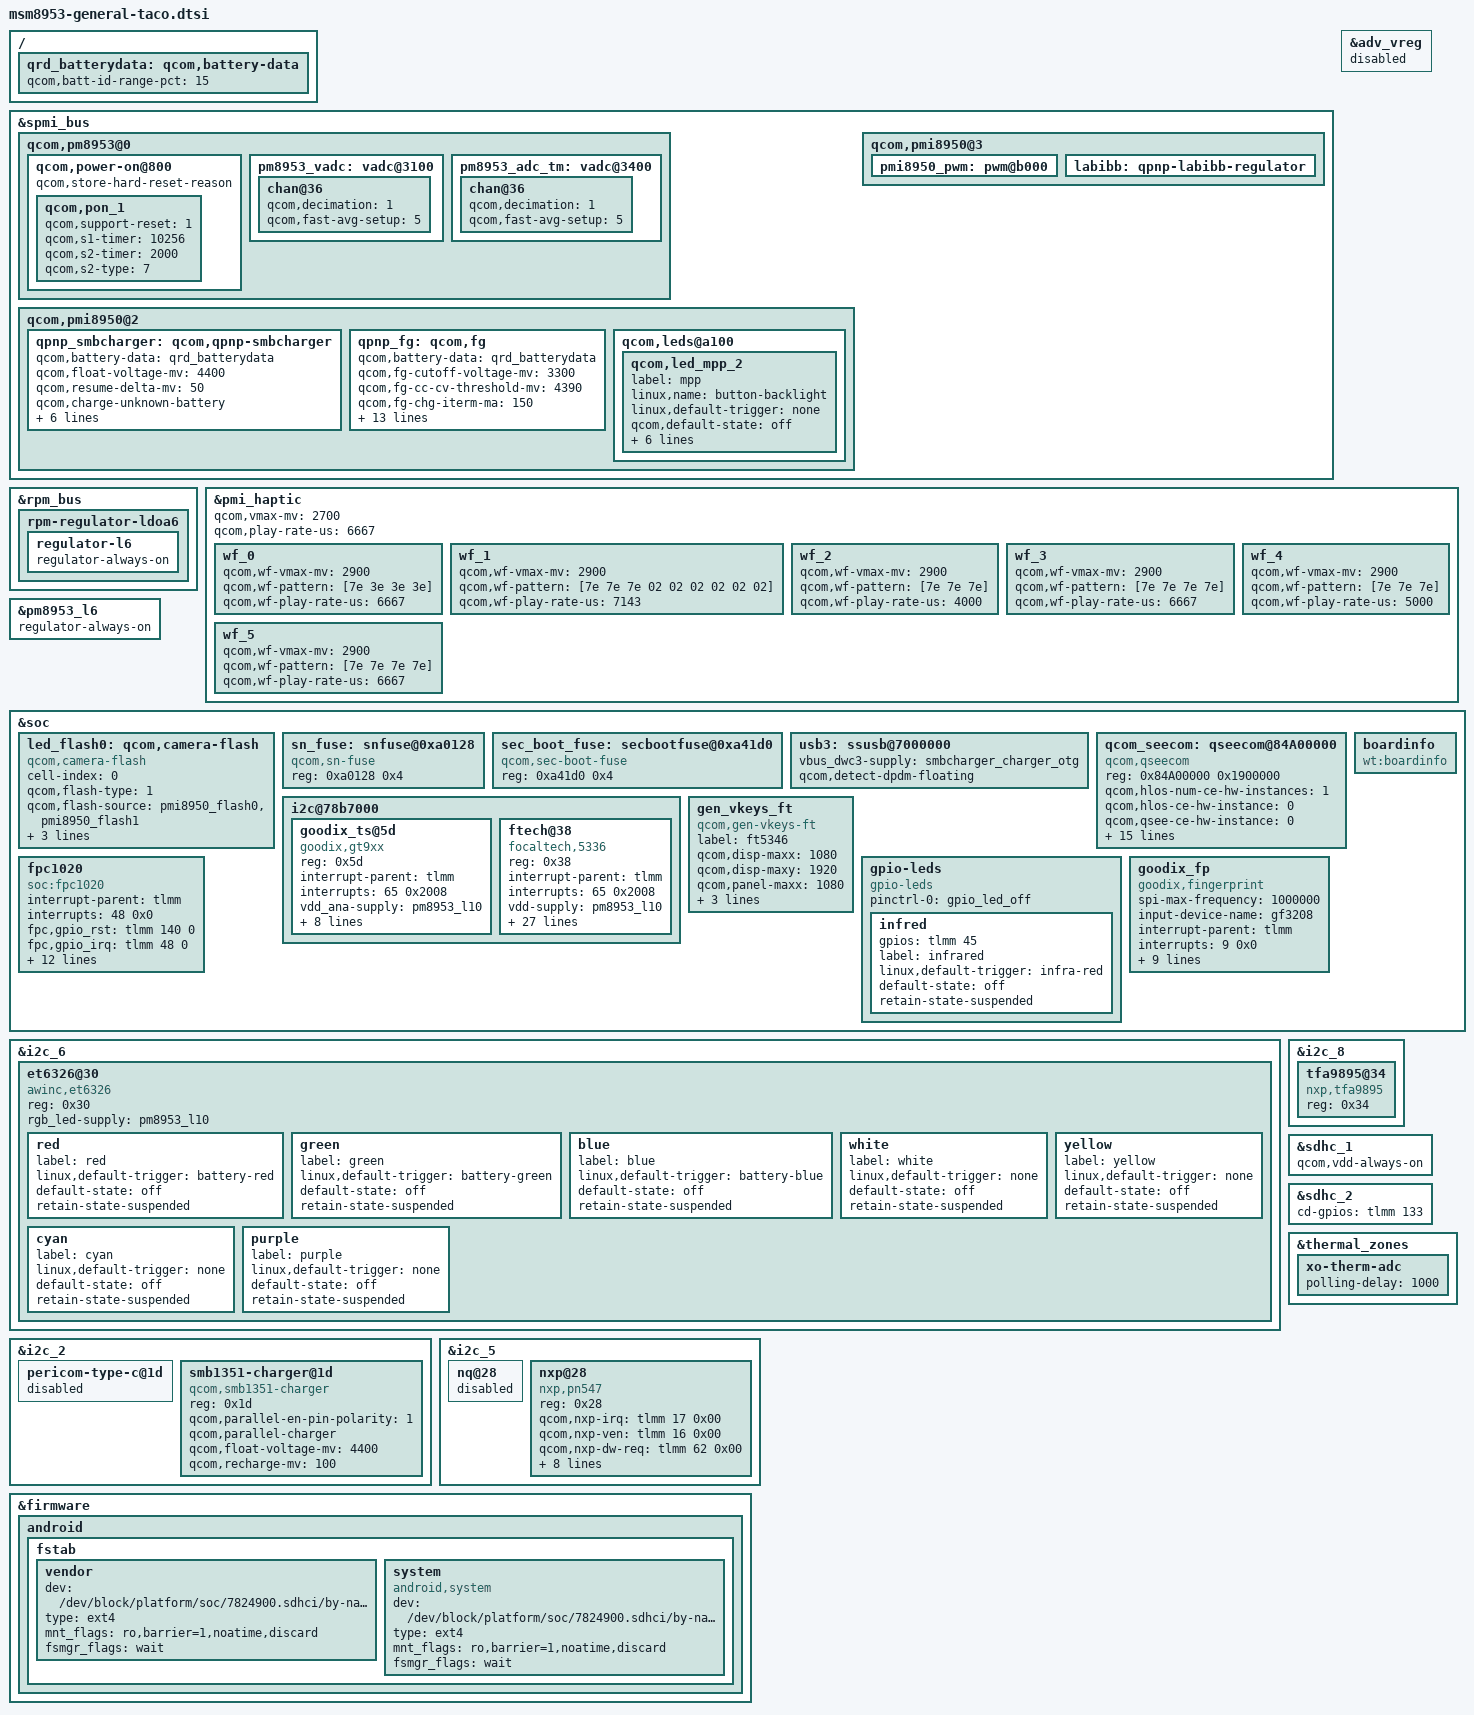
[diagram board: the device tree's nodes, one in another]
/* Copyright (c) 2017, The Linux Foundation. All rights reserved.
 *
 * This program is free software; you can redistribute it and/or modify
 * it under the terms of the GNU General Public License version 2 and
 * only version 2 as published by the Free Software Foundation.
 *
 * This program is distributed in the hope that it will be useful,
 * but WITHOUT ANY WARRANTY; without even the implied warranty of
 * MERCHANTABILITY or FITNESS FOR A PARTICULAR PURPOSE.  See the
 * GNU General Public License for more details.
 */

&spmi_bus {
	qcom,pm8953@0 {
		qcom,power-on@800 {
			qcom,store-hard-reset-reason;
			qcom,pon_1 {
				qcom,support-reset = <1>;
				qcom,s1-timer = <10256>;
				qcom,s2-timer = <2000>;
				qcom,s2-type = <7>;
		    };
	    };

 		/delete-node/ qcom,pm8953_typec@bf00;

		pm8953_vadc: vadc@3100 {
			chan@36 {
				qcom,decimation = <1>;
				qcom,fast-avg-setup = <5>;
			};
		};

		pm8953_adc_tm: vadc@3400 {
			chan@36 {
				qcom,decimation = <1>;
				qcom,fast-avg-setup = <5>;
			};
		};
    };

    qcom,pmi8950@2 {
        qpnp_smbcharger: qcom,qpnp-smbcharger {
            qcom,battery-data = <&qrd_batterydata>;
            qcom,float-voltage-mv = <4400>;
            qcom,resume-delta-mv = <50>;
            qcom,charge-unknown-battery;
            qcom,thermal-mitigation = <2000 1600 1500 1200 1000>;
            qcom,parallel-usb-min-current-ma = <1400>;
            qcom,parallel-usb-9v-min-current-ma = <900>;
            qcom,parallel-allowed-lowering-ma = <500>;
            qcom,autoadjust-vfloat;
            /delete-property/ qcom,chg-led-sw-controls;
            /delete-property/ qcom,chg-led-support;
            /delete-property/ qcom,external-typec;
            /delete-property/ qcom,typec-psy-name;
        };
        qpnp_fg: qcom,fg {
            qcom,battery-data = <&qrd_batterydata>;
            qcom,fg-cutoff-voltage-mv = <3300>;
            qcom,fg-cc-cv-threshold-mv = <4390>;
            qcom,fg-chg-iterm-ma = <150>;
            qcom,fg-iterm-ma = <200>;
            qcom,fg-vbat-estimate-diff-mv = <200>;
            qcom,thermal-coefficients = [DA 86 F0 50 08 3C];
            qcom,cl-max-increment-deciperc = <1>;
            qcom,cl-max-decrement-deciperc = <1>;
            qcom,fg-delta-soc = <1>;
            qcom,cold-hot-jeita-hysteresis = <50 70>;
            qcom,bad-battery-detection-enable;
            qcom,hold-soc-while-full;
            qcom,cold-bat-decidegc = <(-50)>;
            qcom,cool-bat-decidegc = <100>;
            qcom,warm-bat-decidegc = <450>;
            qcom,hot-bat-decidegc = <570>;
        };

        qcom,leds@a100 {
            status = "okay";
            qcom,led_mpp_2 {
			label = "mpp";
			linux,name = "button-backlight";
			linux,default-trigger = "none";
			qcom,default-state = "off";
			qcom,max-current = <40>;
			qcom,current-setting = <3>;
			qcom,id = <6>;
			qcom,mode = "manual";
			qcom,source-sel = <1>;
			qcom,mode-ctrl = <0x60>;
            };
        };
    };

    qcom,pmi8950@3 {
		pmi8950_pwm: pwm@b000 {
			status = "okay";
		};

		labibb: qpnp-labibb-regulator {
			status = "okay";
		};
	};
};

&adv_vreg {
	status = "disabled";
};

&rpm_bus {
    rpm-regulator-ldoa6 {
        regulator-l6 {
            regulator-always-on;
        };
    };
};

&pmi_haptic {
	status = "okay";
	qcom,vmax-mv = <2700>;
	qcom,play-rate-us = <6667>;
	wf_0 {
		qcom,wf-vmax-mv = <2900>;
		qcom,wf-pattern = [7e 3e 3e 3e];
		qcom,wf-play-rate-us = <6667>;
	};
	wf_1 {
		qcom,wf-vmax-mv = <2900>;
		qcom,wf-pattern = [7e 7e 7e 02 02 02 02 02 02];
		qcom,wf-play-rate-us = <7143>;
	};
	wf_2 {
		qcom,wf-vmax-mv = <2900>;
		qcom,wf-pattern = [7e 7e 7e];
		qcom,wf-play-rate-us = <4000>;
	};
	wf_3 {
		qcom,wf-vmax-mv = <2900>;
		qcom,wf-pattern = [7e 7e 7e 7e];
		qcom,wf-play-rate-us = <6667>;
	};
	wf_4 {
		qcom,wf-vmax-mv = <2900>;
		qcom,wf-pattern = [7e 7e 7e];
		qcom,wf-play-rate-us = <5000>;
	};
	wf_5 {
		qcom,wf-vmax-mv = <2900>;
		qcom,wf-pattern = [7e 7e 7e 7e];
		qcom,wf-play-rate-us = <6667>;
	};
};

&pmi8950_pwm {
    status = "okay";
};

&pm8953_l6 {
	regulator-always-on;
};

&soc {
	led_flash0: qcom,camera-flash {
		cell-index = <0>;
		compatible = "qcom,camera-flash";
		qcom,flash-type = <1>;
		qcom,flash-source = <&pmi8950_flash0 &pmi8950_flash1>;
		qcom,torch-source = <&pmi8950_torch0 &pmi8950_torch1 &pmi8950_torch2>;
		qcom,switch-source = <&pmi8950_switch>;
	};

	sn_fuse: snfuse@0xa0128 {
		compatible = "qcom,sn-fuse";
		reg = <0xa0128 0x4>;
		reg-names = "sn-base";
	};

	sec_boot_fuse: secbootfuse@0xa41d0 {
		compatible = "qcom,sec-boot-fuse";
		reg = <0xa41d0 0x4>;
		reg-names = "sec-boot-base";
	};

	usb3: ssusb@7000000 {
		vbus_dwc3-supply = <&smbcharger_charger_otg>;
		qcom,detect-dpdm-floating;
	};

	qcom_seecom: qseecom@84A00000 {
		compatible = "qcom,qseecom";
		reg = <0x84A00000 0x1900000>;
		reg-names = "secapp-region";
		qcom,hlos-num-ce-hw-instances = <1>;
		qcom,hlos-ce-hw-instance = <0>;
		qcom,qsee-ce-hw-instance = <0>;
		qcom,disk-encrypt-pipe-pair = <2>;
		qcom,support-fde;
		qcom,msm-bus,name = "qseecom-noc";
		qcom,msm-bus,num-cases = <4>;
		qcom,msm-bus,num-paths = <1>;
		qcom,support-bus-scaling;
		qcom,appsbl-qseecom-support;
		qcom,msm-bus,vectors-KBps =
			<55 512 0 0>,
			<55 512 0 0>,
			<55 512 120000 1200000>,
			<55 512 393600 3936000>;
		clocks = <&clock_gcc clk_crypto_clk_src>,
			 <&clock_gcc clk_gcc_crypto_clk>,
			 <&clock_gcc clk_gcc_crypto_ahb_clk>,
			 <&clock_gcc clk_gcc_crypto_axi_clk>;
		clock-names = "core_clk_src", "core_clk",
				"iface_clk", "bus_clk";
		qcom,ce-opp-freq = <100000000>;
	};

	/delete-node/ qseecom@85b00000;

	i2c@78b7000 { /* BLSP1 QUP3 */
		/delete-node/ synaptics@4b;
		goodix_ts@5d {
			compatible = "goodix,gt9xx";
			reg = <0x5d>;	
			interrupt-parent = <&tlmm>;
			interrupts = <65 0x2008>;
			vdd_ana-supply = <&pm8953_l10>;
			vcc_i2c-supply = <&pm8953_l5>;
			pinctrl-names = "pmx_ts_active","pmx_ts_suspend",
                        "pmx_ts_release";
                        pinctrl-0 = <&ts_int_active &ts_reset_active>;
                        pinctrl-1 = <&ts_int_suspend &ts_reset_suspend>;
                        pinctrl-2 = <&ts_release>;
			goodix,rst-gpio = <&tlmm 64 0x00>;
			goodix,irq-gpio = <&tlmm 65 0x2008>;
			goodix,cfg-group0 = [
				41 D0 02 00 05 05 75 01 01 0F 24 
				0F 64 3C 03 05 00 00 00 02 00 00 
				00 16 19 1C 14 8C 0E 0E 24 00 31 
				0D 00 00 00 83 33 1D 00 41 00 00 
				00 00 00 08 0A 00 2B 1C 3C 94 D5 
				03 08 00 00 04 93 1E 00 82 23 00 
				74 29 00 69 2F 00 5F 37 00 5F 20 
				40 60 00 F0 40 30 55 50 27 00 00 
				00 00 00 00 00 00 00 00 00 00 00 
				00 00 00 00 00 00 00 14 19 00 00 
				50 50 02 04 06 08 0A 0C 0E 10 12 
				14 16 18 1A 1C 00 00 00 00 00 00 
				00 00 00 00 00 00 00 00 00 00 1D 
				1E 1F 20 21 22 24 26 28 29 2A 1C 
				18 16 14 13 12 10 0F 0C 0A 08 06 
				04 02 00 00 00 00 00 00 00 00 00 
				00 00 00 00 00 00 00 00 9C 01];
		};
		ftech@38 {
			compatible = "focaltech,5336";
			reg = <0x38>;
			interrupt-parent = <&tlmm>;
			interrupts = <65 0x2008>;
			vdd-supply = <&pm8953_l10>;
			vcc_i2c-supply = <&pm8953_l5>;
			/* pins used by touchscreen */
			pinctrl-names = "pmx_ts_active","pmx_ts_suspend",
				"pmx_ts_release";
			pinctrl-0 = <&ts_int_active &ts_reset_active>;
			pinctrl-1 = <&ts_int_suspend &ts_reset_suspend>;
			pinctrl-2 = <&ts_release>;
			ftech,name = "ft5336";
			ftech,family-id = <0x36>;
			ftech,reset-gpio = <&tlmm 64 0x00>;
			ftech,irq-gpio = <&tlmm 65 0x2008>;
			ftech,display-coords = <0 0 1080 1920>;
			ftech,panel-coords = <0 0 1080 1920>;
			/*ftech,button-map= <139 102 158>;*/
			ftech,virtual-key1 = <139 180 2000>;/*menu*/
			ftech,virtual-key2 = <172 540 2000>;/*home*/
			ftech,virtual-key3 = <158 900 2000>;/*back*/
			ftech,no-force-update;
			ftech,i2c-pull-up;
			ftech,group-id = <1>;
			ftech,hard-reset-delay-ms = <20>;
			ftech,soft-reset-delay-ms = <200>;
			ftech,num-max-touches = <10>;
			ftech,fw-delay-aa-ms = <30>;
			ftech,fw-delay-55-ms = <30>;
			ftech,fw-upgrade-id1 = <0x79>;
			ftech,fw-upgrade-id2 = <0x18>;
			ftech,fw-delay-readid-ms = <10>;
			ftech,fw-delay-era-flsh-ms = <2000>;
			ftech,fw-auto-cal;
			ftech,ignore-id-check;
		};
	};
	gen_vkeys_ft {
		compatible = "qcom,gen-vkeys-ft";
		label = "ft5346";
		qcom,disp-maxx = <1080>;
		qcom,disp-maxy = <1920>;
		qcom,panel-maxx = <1080>;
		qcom,panel-maxy = <2080>;
		qcom,key-codes = <139 172 158>;
		qcom,y-offset = <0>;
	};

	gpio-leds {
		compatible = "gpio-leds";
		status = "okay";
		pinctrl-names = "default";
		pinctrl-0 = <&gpio_led_off>;

			infred {
			gpios = <&tlmm 45 0>;
			label = "infrared";
			linux,default-trigger = "infra-red";
			default-state = "off";
			retain-state-suspended;
		};
	};

	fpc1020 {
		compatible = "soc:fpc1020";

		interrupt-parent = <&tlmm>;
		interrupts = <48 0x0>;

		fpc,gpio_rst    = <&tlmm 140 0>;
		fpc,gpio_irq    = <&tlmm 48 0>;
		fpc,gpio_1do    = <&tlmm 134 0>;

		vcc_spi-supply  = <&pm8953_l5>;
		vdd_ana-supply  = <&pm8953_l5>;
		vdd_io-supply   = <&pm8953_l5>;

		fpc,enable-on-boot;
		/delete-property/
		fpc,enable-wakeup;

		fpc,spi-max-frequency = <4800000>;

		/*For SPI Clock Handled by Linux*/
		clock-names = "iface_clk", "core_clk";
		clocks = <&clock_gcc clk_gcc_blsp1_ahb_clk>,
			<&clock_gcc clk_gcc_blsp1_qup1_spi_apps_clk>;

		pinctrl-names = "fpc1020_spi_active",
				"fpc1020_reset_reset",
				"fpc1020_reset_active",
				"fpc1020_irq_active";

		pinctrl-0 = <&fpc_spi_active>;
		pinctrl-1 = <&fpc_reset_reset>;
		pinctrl-2 = <&fpc_reset_active>;
		pinctrl-3 = <&fpc_irq_active>;
	};

      goodix_fp {
		compatible = "goodix,fingerprint";
		spi-max-frequency = <1000000>;
		input-device-name = "gf3208";
		interrupt-parent = <&tlmm>;
		interrupts = <9 0x0>;

		goodix,gpio_reset    = <&tlmm 140 0>;
		goodix,gpio_irq      = <&tlmm 48 0>;
		goodix,gpio_1do    = <&tlmm 134 0>;
			
		clock-names = "iface_clk", "core_clk";
		clocks = <&clock_gcc clk_gcc_blsp1_ahb_clk>,
		<&clock_gcc clk_gcc_blsp1_qup1_spi_apps_clk>;

		pinctrl-names = "goodixfp_spi_active",
				"goodixfp_reset_reset",
				"goodixfp_reset_active",
				"goodixfp_irq_active";

		pinctrl-0 = <&goodix_spi_active>;
		pinctrl-1 = <&goodix_reset_reset>;
		pinctrl-2 = <&goodix_reset_active>;
		pinctrl-3 = <&goodix_irq_active>;
	};

	boardinfo {
		compatible = "wt:boardinfo";
	};
};

&i2c_6  { /* i2c 6 */
	et6326@30 { /*blink */
		compatible = "awinc,et6326";
		reg = <0x30>;
		rgb_led-supply = <&pm8953_l10>;
		
		red {
			label = "red";
			linux,default-trigger = "battery-red";
			default-state = "off";
			retain-state-suspended;
		};

		green {
			label = "green";
			linux,default-trigger = "battery-green";
			default-state = "off";
			retain-state-suspended;
		};

		blue {
			label = "blue";
			linux,default-trigger = "battery-blue";
			default-state = "off";
			retain-state-suspended;
		};
		white {
			label = "white";
			linux,default-trigger = "none";
			default-state = "off";
			retain-state-suspended;
		};

		yellow {
			label = "yellow";
			linux,default-trigger = "none";
			default-state = "off";
			retain-state-suspended;
		};

		cyan {
			label = "cyan";
			linux,default-trigger = "none";
			default-state = "off";
			retain-state-suspended;
		};
		purple {
			label = "purple";
			linux,default-trigger = "none";
			default-state = "off";
			retain-state-suspended;
		};				
		
	};
};

/*audio bring up ,zhangjianming2.wt start*/
&i2c_8  {
	tfa9895@34 { /*tfa9895 */
		compatible = "nxp,tfa9895";
		reg = <0x34>;
	};
};
/*audio bring up ,zhangjianming2.wt end*/

&sdhc_1 {
	/* emmc5.0 of hynix flash */
	qcom,vdd-always-on;
};

&sdhc_2 {
	cd-gpios = <&tlmm 133 0x0>;
};

&i2c_2 {
	pericom-type-c@1d {
		status="disabled";
	};
	/* Parallel-charger configuration */
	smb1351-charger@1d {
		compatible = "qcom,smb1351-charger";
		reg = <0x1d>;
		qcom,parallel-en-pin-polarity = <1>;
		qcom,parallel-charger;
		qcom,float-voltage-mv = <4400>;
		qcom,recharge-mv = <100>;
	};
};

&i2c_5 { /* BLSP2 QUP1 (NFC) */
        status = "ok";

	nq@28 {
		status = "disabled";
	};
	
    nxp@28 {
            compatible = "nxp,pn547";
            reg = <0x28>;
            qcom,nxp-irq = <&tlmm 17 0x00>;
            qcom,nxp-ven = <&tlmm 16 0x00>;
            qcom,nxp-dw-req = <&tlmm 62 0x00>;
            qcom,nxp-clkreq = <&pm8953_gpios 2 0x00>;
            interrupt-parent = <&tlmm>;
            qcom,clk-src = "BBCLK2";
            interrupts = <17 0>;
            interrupt-names = "nxp-irq";
            pinctrl-names = "nfc_active", "nfc_suspend";
            pinctrl-0 = <&nfc_int_active &nfc_disable_active>;
            pinctrl-1 = <&nfc_int_suspend &nfc_disable_suspend>;
            clocks = <&clock_gcc clk_bb_clk2_pin>;
            clock-names = "ref_clk";
    };
};

&thermal_zones {
	xo-therm-adc {
		polling-delay = <1000>;
	};
};

/ {
	/delete-node/ qcom,battery-data;
	qrd_batterydata: qcom,battery-data {
		qcom,batt-id-range-pct = <15>;

		#include "battery/B5W-qrd-Coslight-4v4-4000mah.dtsi"
		#include "battery/n2-qrd-atl-4000mah.dtsi"
		#include "battery/Drn-3950mah.dtsi"
	};
};

&firmware {
	android {
		/delete-node/ vbmeta;

		fstab {
			vendor {
				dev = "/dev/block/platform/soc/7824900.sdhci/by-name/cust";
				type = "ext4";
				mnt_flags = "ro,barrier=1,noatime,discard";
				fsmgr_flags = "wait";
				status = "ok";
			};

			system {
				compatible = "android,system";
				dev = "/dev/block/platform/soc/7824900.sdhci/by-name/system";
				type = "ext4";
				mnt_flags = "ro,barrier=1,noatime,discard";
				fsmgr_flags = "wait";
				status = "ok";
			};
		};
	};
};
